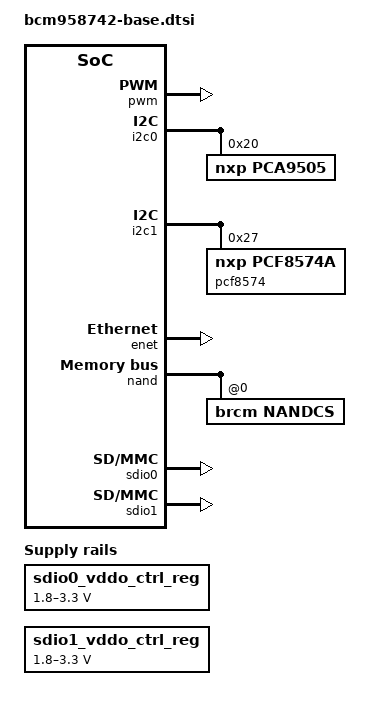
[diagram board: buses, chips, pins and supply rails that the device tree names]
#include "stingray-board-base.dtsi"
/ {
	sdio0_vddo_ctrl_reg: sdio0_vddo_ctrl {
		compatible = "regulator-gpio";
		regulator-name = "sdio0_vddo_ctrl_reg";
		regulator-type = "voltage";
		regulator-min-microvolt = <1800000>;
		regulator-max-microvolt = <3300000>;
		gpios = <&pca9505 18 0>;
		states = <3300000 0x0
			  1800000 0x1>;
	};
	sdio1_vddo_ctrl_reg: sdio1_vddo_ctrl {
		compatible = "regulator-gpio";
		regulator-name = "sdio1_vddo_ctrl_reg";
		regulator-type = "voltage";
		regulator-min-microvolt = <1800000>;
		regulator-max-microvolt = <3300000>;
		gpios = <&pca9505 19 0>;
		states = <3300000 0x0
			  1800000 0x1>;
	};
};
&pwm {
	status = "okay";
};
&i2c0 {
	status = "okay";
	pca9505: pca9505@20 {
		compatible = "nxp,pca9505";
		gpio-controller;
		#gpio-cells = <2>;
		reg = <0x20>;
	};
};
&i2c1 {
	status = "okay";
	pcf8574: pcf8574@27 {
		compatible = "nxp,pcf8574a";
		gpio-controller;
		#gpio-cells = <2>;
		reg = <0x27>;
	};
};
&enet {
	status = "okay";
};
&nand {
	status = "okay";
	nandcs@0 {
		compatible = "brcm,nandcs";
		reg = <0>;
		nand-ecc-mode = "hw";
		nand-ecc-strength = <8>;
		nand-ecc-step-size = <512>;
		nand-bus-width = <16>;
		brcm,nand-oob-sector-size = <16>;
		#address-cells = <1>;
		#size-cells = <1>;
	};
};
&sdio0 {
	vqmmc-supply = <&sdio0_vddo_ctrl_reg>;
	status = "okay";
};
&sdio1 {
	vqmmc-supply = <&sdio1_vddo_ctrl_reg>;
	status = "okay";
};
